VERSION ""

NS_ :

BS_:

BU_: ECU_Engine ECU_Transmission ECU_ABS ECU_Body Gateway Cluster Diagnostic

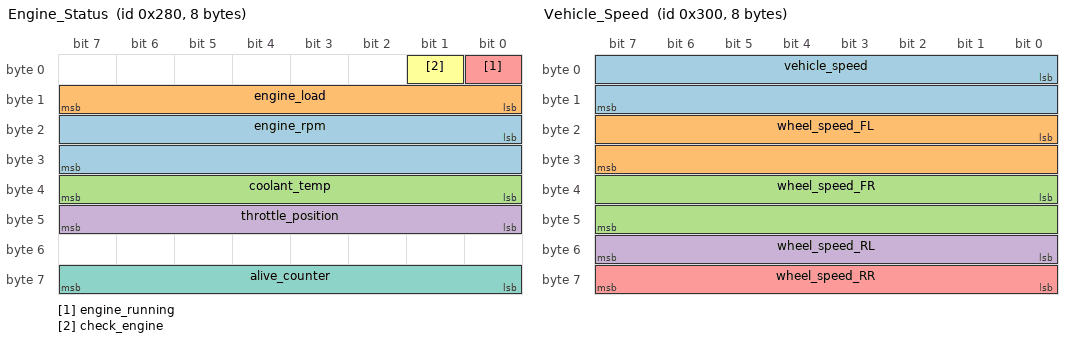
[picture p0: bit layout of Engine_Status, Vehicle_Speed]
BO_ 640 Engine_Status: 8 ECU_Engine
 SG_ engine_rpm : 16|16@1+ (0.25,0) [0|8000] "rpm" Cluster
 SG_ engine_load : 8|8@1+ (0.3921569,0) [0|100] "%" Cluster
 SG_ coolant_temp : 32|8@1+ (1,-40) [-40|215] "degC" Cluster
 SG_ throttle_position : 40|8@1+ (0.3921569,0) [0|100] "%" Cluster
 SG_ engine_running : 0|1@1+ (1,0) [0|1] "" Cluster
 SG_ check_engine : 1|1@1+ (1,0) [0|1] "" Cluster
 SG_ alive_counter : 56|8@1+ (1,0) [0|255] "" Cluster

BO_ 768 Vehicle_Speed: 8 ECU_ABS
 SG_ vehicle_speed : 0|16@1+ (0.01,0) [0|250] "km/h" Cluster
 SG_ wheel_speed_FL : 16|16@1+ (0.01,0) [0|250] "km/h" ECU_ABS
 SG_ wheel_speed_FR : 32|16@1+ (0.01,0) [0|250] "km/h" ECU_ABS
 SG_ wheel_speed_RL : 48|8@1+ (1,0) [0|250] "km/h" ECU_ABS
 SG_ wheel_speed_RR : 56|8@1+ (1,0) [0|250] "km/h" ECU_ABS

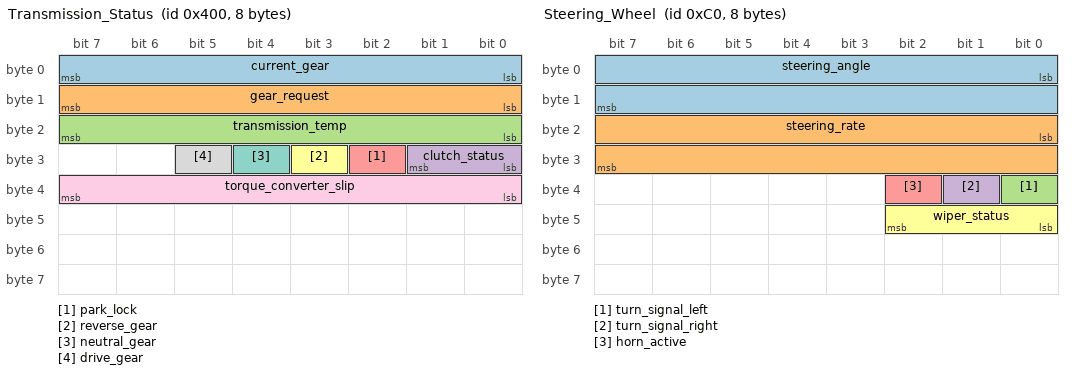
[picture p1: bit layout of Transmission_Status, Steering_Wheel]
BO_ 1024 Transmission_Status: 8 ECU_Transmission
 SG_ current_gear : 0|8@1+ (1,0) [0|8] "" Cluster
 SG_ gear_request : 8|8@1+ (1,0) [0|8] "" ECU_Transmission
 SG_ transmission_temp : 16|8@1+ (1,-40) [-40|150] "degC" Cluster
 SG_ clutch_status : 24|2@1+ (1,0) [0|3] "" ECU_Transmission
 SG_ park_lock : 26|1@1+ (1,0) [0|1] "" ECU_Transmission
 SG_ reverse_gear : 27|1@1+ (1,0) [0|1] "" Cluster
 SG_ neutral_gear : 28|1@1+ (1,0) [0|1] "" Cluster
 SG_ drive_gear : 29|1@1+ (1,0) [0|1] "" Cluster
 SG_ torque_converter_slip : 32|8@1+ (0.390625,0) [0|100] "%" ECU_Transmission

BO_ 192 Steering_Wheel: 8 ECU_Body
 SG_ steering_angle : 0|16@1- (0.043,0) [-780|780] "deg" ECU_ABS
 SG_ steering_rate : 16|16@1- (0.5,0) [-1000|1000] "deg/s" ECU_ABS
 SG_ turn_signal_left : 32|1@1+ (1,0) [0|1] "" Cluster
 SG_ turn_signal_right : 33|1@1+ (1,0) [0|1] "" Cluster
 SG_ horn_active : 34|1@1+ (1,0) [0|1] "" ECU_Body
 SG_ wiper_status : 40|3@1+ (1,0) [0|7] "" ECU_Body

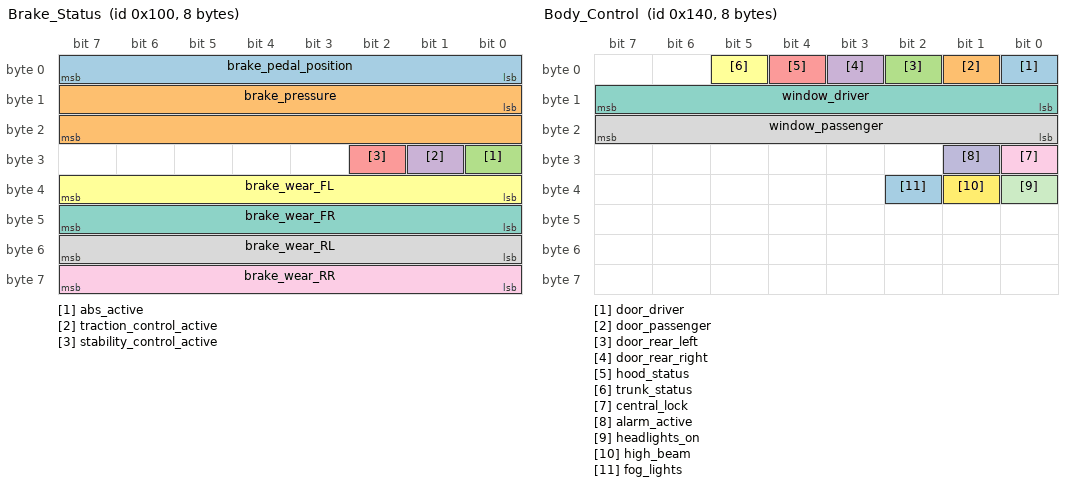
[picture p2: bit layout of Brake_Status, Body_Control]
BO_ 256 Brake_Status: 8 ECU_ABS
 SG_ brake_pedal_position : 0|8@1+ (0.3921569,0) [0|100] "%" ECU_Engine
 SG_ brake_pressure : 8|16@1+ (0.1,0) [0|300] "bar" ECU_ABS
 SG_ abs_active : 24|1@1+ (1,0) [0|1] "" Cluster
 SG_ traction_control_active : 25|1@1+ (1,0) [0|1] "" Cluster
 SG_ stability_control_active : 26|1@1+ (1,0) [0|1] "" Cluster
 SG_ brake_wear_FL : 32|8@1+ (0.3921569,0) [0|100] "%" Cluster
 SG_ brake_wear_FR : 40|8@1+ (0.3921569,0) [0|100] "%" Cluster
 SG_ brake_wear_RL : 48|8@1+ (0.3921569,0) [0|100] "%" Cluster
 SG_ brake_wear_RR : 56|8@1+ (0.3921569,0) [0|100] "%" Cluster

BO_ 320 Body_Control: 8 ECU_Body
 SG_ door_driver : 0|1@1+ (1,0) [0|1] "" Cluster
 SG_ door_passenger : 1|1@1+ (1,0) [0|1] "" Cluster
 SG_ door_rear_left : 2|1@1+ (1,0) [0|1] "" Cluster
 SG_ door_rear_right : 3|1@1+ (1,0) [0|1] "" Cluster
 SG_ hood_status : 4|1@1+ (1,0) [0|1] "" Cluster
 SG_ trunk_status : 5|1@1+ (1,0) [0|1] "" Cluster
 SG_ window_driver : 8|8@1+ (0.3921569,0) [0|100] "%" ECU_Body
 SG_ window_passenger : 16|8@1+ (0.3921569,0) [0|100] "%" ECU_Body
 SG_ central_lock : 24|1@1+ (1,0) [0|1] "" ECU_Body
 SG_ alarm_active : 25|1@1+ (1,0) [0|1] "" Cluster
 SG_ headlights_on : 32|1@1+ (1,0) [0|1] "" Cluster
 SG_ high_beam : 33|1@1+ (1,0) [0|1] "" Cluster
 SG_ fog_lights : 34|1@1+ (1,0) [0|1] "" ECU_Body

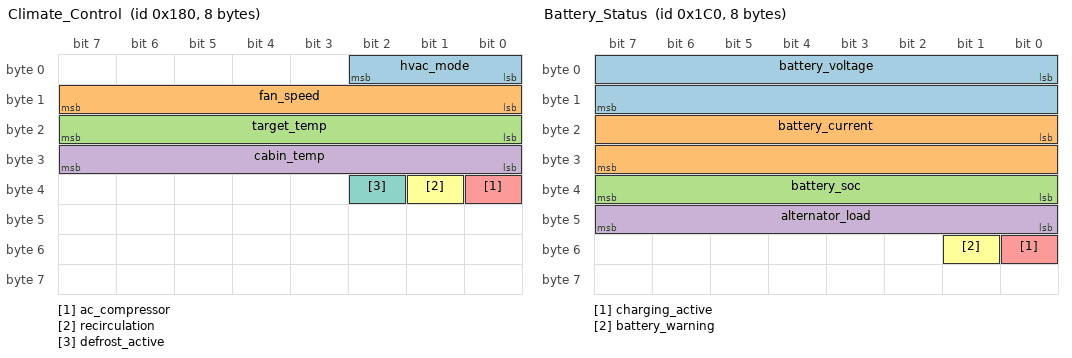
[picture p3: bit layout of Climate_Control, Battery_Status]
BO_ 384 Climate_Control: 8 ECU_Body
 SG_ hvac_mode : 0|3@1+ (1,0) [0|7] "" ECU_Body
 SG_ fan_speed : 8|8@1+ (1,0) [0|15] "" ECU_Body
 SG_ target_temp : 16|8@1+ (0.5,15) [15|30] "degC" ECU_Body
 SG_ cabin_temp : 24|8@1+ (0.5,-40) [-40|85] "degC" ECU_Body
 SG_ ac_compressor : 32|1@1+ (1,0) [0|1] "" ECU_Body
 SG_ recirculation : 33|1@1+ (1,0) [0|1] "" ECU_Body
 SG_ defrost_active : 34|1@1+ (1,0) [0|1] "" ECU_Body

BO_ 448 Battery_Status: 8 ECU_Engine
 SG_ battery_voltage : 0|16@1+ (0.01,0) [0|20] "V" Cluster
 SG_ battery_current : 16|16@1- (0.1,0) [-200|200] "A" ECU_Engine
 SG_ battery_soc : 32|8@1+ (0.5,0) [0|100] "%" Cluster
 SG_ alternator_load : 40|8@1+ (0.3921569,0) [0|100] "%" ECU_Engine
 SG_ charging_active : 48|1@1+ (1,0) [0|1] "" ECU_Engine
 SG_ battery_warning : 49|1@1+ (1,0) [0|1] "" Cluster

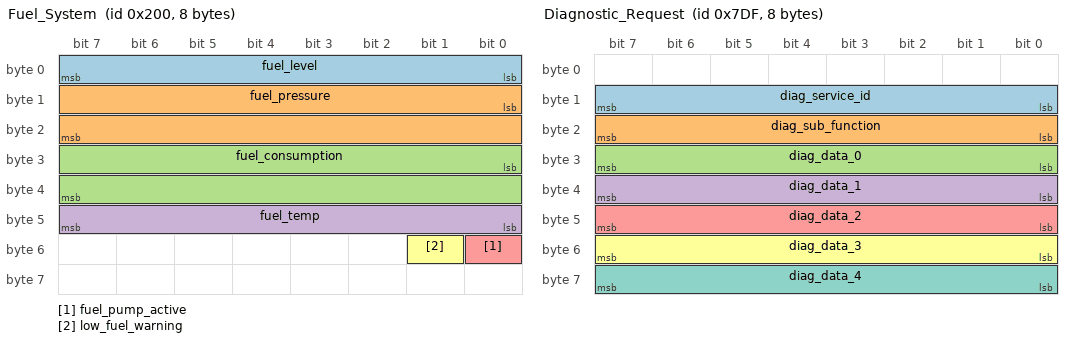
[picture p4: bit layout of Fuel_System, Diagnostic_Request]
BO_ 512 Fuel_System: 8 ECU_Engine
 SG_ fuel_level : 0|8@1+ (0.3921569,0) [0|100] "%" Cluster
 SG_ fuel_pressure : 8|16@1+ (0.1,0) [0|1000] "kPa" ECU_Engine
 SG_ fuel_consumption : 24|16@1+ (0.01,0) [0|100] "L/h" Cluster
 SG_ fuel_temp : 40|8@1+ (1,-40) [-40|120] "degC" ECU_Engine
 SG_ fuel_pump_active : 48|1@1+ (1,0) [0|1] "" ECU_Engine
 SG_ low_fuel_warning : 49|1@1+ (1,0) [0|1] "" Cluster

BO_ 2015 Diagnostic_Request: 8 Diagnostic
 SG_ diag_service_id : 8|8@1+ (1,0) [0|255] "" ECU_Engine,ECU_Transmission,ECU_ABS,ECU_Body
 SG_ diag_sub_function : 16|8@1+ (1,0) [0|255] "" ECU_Engine,ECU_Transmission,ECU_ABS,ECU_Body
 SG_ diag_data_0 : 24|8@1+ (1,0) [0|255] "" ECU_Engine,ECU_Transmission,ECU_ABS,ECU_Body
 SG_ diag_data_1 : 32|8@1+ (1,0) [0|255] "" ECU_Engine,ECU_Transmission,ECU_ABS,ECU_Body
 SG_ diag_data_2 : 40|8@1+ (1,0) [0|255] "" ECU_Engine,ECU_Transmission,ECU_ABS,ECU_Body
 SG_ diag_data_3 : 48|8@1+ (1,0) [0|255] "" ECU_Engine,ECU_Transmission,ECU_ABS,ECU_Body
 SG_ diag_data_4 : 56|8@1+ (1,0) [0|255] "" ECU_Engine,ECU_Transmission,ECU_ABS,ECU_Body

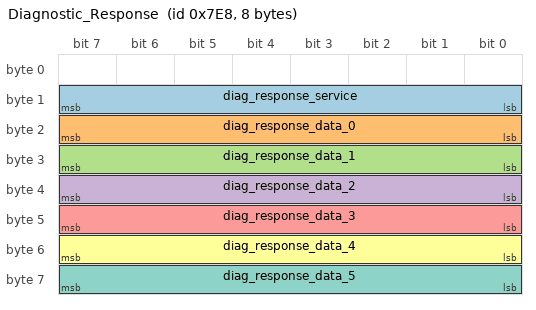
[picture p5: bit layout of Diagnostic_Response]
BO_ 2024 Diagnostic_Response: 8 ECU_Engine
 SG_ diag_response_service : 8|8@1+ (1,0) [0|255] "" Diagnostic
 SG_ diag_response_data_0 : 16|8@1+ (1,0) [0|255] "" Diagnostic
 SG_ diag_response_data_1 : 24|8@1+ (1,0) [0|255] "" Diagnostic
 SG_ diag_response_data_2 : 32|8@1+ (1,0) [0|255] "" Diagnostic
 SG_ diag_response_data_3 : 40|8@1+ (1,0) [0|255] "" Diagnostic
 SG_ diag_response_data_4 : 48|8@1+ (1,0) [0|255] "" Diagnostic
 SG_ diag_response_data_5 : 56|8@1+ (1,0) [0|255] "" Diagnostic

CM_ BU_ ECU_Engine "Engine Control Unit";
CM_ BU_ ECU_Transmission "Transmission Control Unit";
CM_ BU_ ECU_ABS "Anti-lock Braking System / Electronic Stability Control";
CM_ BU_ ECU_Body "Body Control Module";
CM_ BU_ Gateway "CAN Gateway";
CM_ BU_ Cluster "Instrument Cluster";
CM_ BU_ Diagnostic "Diagnostic Tester";

CM_ BO_ 640 "Engine status and vital parameters";
CM_ BO_ 768 "Vehicle and wheel speeds from ABS module";
CM_ BO_ 1024 "Transmission status and gear information";
CM_ BO_ 192 "Steering wheel position and controls";
CM_ BO_ 256 "Brake system status and pressure";
CM_ BO_ 320 "Body control (doors, windows, lights)";
CM_ BO_ 384 "HVAC and climate control";
CM_ BO_ 448 "Battery and charging system";
CM_ BO_ 512 "Fuel system monitoring";
CM_ BO_ 2015 "OBD-II / UDS diagnostic request (0x7DF)";
CM_ BO_ 2024 "OBD-II / UDS diagnostic response (0x7E8)";

CM_ SG_ 640 engine_rpm "Engine speed in revolutions per minute";
CM_ SG_ 640 engine_load "Calculated engine load percentage";
CM_ SG_ 640 coolant_temp "Engine coolant temperature";
CM_ SG_ 640 throttle_position "Throttle pedal position percentage";
CM_ SG_ 640 engine_running "Engine running status (0=off, 1=running)";
CM_ SG_ 640 check_engine "Check engine light / MIL status";
CM_ SG_ 640 alive_counter "Rolling counter for message aliveness";

CM_ SG_ 768 vehicle_speed "Vehicle speed calculated from wheel speeds";
CM_ SG_ 768 wheel_speed_FL "Front left wheel speed";
CM_ SG_ 768 wheel_speed_FR "Front right wheel speed";
CM_ SG_ 768 wheel_speed_RL "Rear left wheel speed";
CM_ SG_ 768 wheel_speed_RR "Rear right wheel speed";

CM_ SG_ 1024 current_gear "Current engaged gear (0=Neutral, 1-8=Drive gears)";
CM_ SG_ 1024 transmission_temp "Transmission oil temperature";
CM_ SG_ 1024 park_lock "Park lock engaged (0=unlocked, 1=locked)";

CM_ SG_ 192 steering_angle "Steering wheel angle (negative=left, positive=right)";
CM_ SG_ 192 steering_rate "Rate of steering wheel rotation";

CM_ SG_ 256 brake_pedal_position "Brake pedal position percentage";
CM_ SG_ 256 brake_pressure "Hydraulic brake pressure";
CM_ SG_ 256 abs_active "ABS intervention active";
CM_ SG_ 256 traction_control_active "Traction control active";
CM_ SG_ 256 stability_control_active "Electronic stability control active";

CM_ SG_ 320 door_driver "Driver door status (0=closed, 1=open)";
CM_ SG_ 320 central_lock "Central locking engaged";
CM_ SG_ 320 alarm_active "Security alarm triggered";

CM_ SG_ 448 battery_voltage "12V battery voltage";
CM_ SG_ 448 battery_current "Battery current (positive=charging, negative=discharging)";
CM_ SG_ 448 battery_soc "Battery state of charge";

CM_ SG_ 512 fuel_level "Fuel tank level percentage";
CM_ SG_ 512 fuel_consumption "Instantaneous fuel consumption rate";

BA_DEF_ "BusType" STRING ;
BA_DEF_ BO_ "GenMsgCycleTime" INT 0 10000;
BA_DEF_ BO_ "GenMsgSendType" STRING ;

BA_DEF_DEF_ "BusType" "CAN";
BA_DEF_DEF_ "GenMsgCycleTime" 0;
BA_DEF_DEF_ "GenMsgSendType" "cyclic";

BA_ "GenMsgCycleTime" BO_ 640 10;
BA_ "GenMsgCycleTime" BO_ 768 20;
BA_ "GenMsgCycleTime" BO_ 1024 50;
BA_ "GenMsgCycleTime" BO_ 192 10;
BA_ "GenMsgCycleTime" BO_ 256 10;
BA_ "GenMsgCycleTime" BO_ 320 100;
BA_ "GenMsgCycleTime" BO_ 384 200;
BA_ "GenMsgCycleTime" BO_ 448 1000;
BA_ "GenMsgCycleTime" BO_ 512 500;
BA_ "GenMsgSendType" BO_ 2015 "event";
BA_ "GenMsgSendType" BO_ 2024 "event";

VAL_ 640 engine_running 0 "Engine_Off" 1 "Engine_Running" ;
VAL_ 640 check_engine 0 "No_Fault" 1 "Malfunction_Indicator_Lamp" ;
VAL_ 1024 current_gear 0 "Neutral" 1 "First" 2 "Second" 3 "Third" 4 "Fourth" 5 "Fifth" 6 "Sixth" 7 "Seventh" 8 "Eighth" ;
VAL_ 1024 clutch_status 0 "Released" 1 "Partial" 2 "Engaged" 3 "Unknown" ;
VAL_ 1024 park_lock 0 "Unlocked" 1 "Locked" ;
VAL_ 1024 reverse_gear 0 "Not_Reverse" 1 "Reverse" ;
VAL_ 1024 neutral_gear 0 "Not_Neutral" 1 "Neutral" ;
VAL_ 1024 drive_gear 0 "Not_Drive" 1 "Drive" ;
VAL_ 192 turn_signal_left 0 "Off" 1 "Blinking" ;
VAL_ 192 turn_signal_right 0 "Off" 1 "Blinking" ;
VAL_ 192 horn_active 0 "Off" 1 "Active" ;
VAL_ 192 wiper_status 0 "Off" 1 "Intermittent_1" 2 "Intermittent_2" 3 "Intermittent_3" 4 "Low" 5 "Medium" 6 "High" 7 "Wash" ;
VAL_ 256 abs_active 0 "Inactive" 1 "Active" ;
VAL_ 256 traction_control_active 0 "Inactive" 1 "Active" ;
VAL_ 256 stability_control_active 0 "Inactive" 1 "Active" ;
VAL_ 320 door_driver 0 "Closed" 1 "Open" ;
VAL_ 320 door_passenger 0 "Closed" 1 "Open" ;
VAL_ 320 door_rear_left 0 "Closed" 1 "Open" ;
VAL_ 320 door_rear_right 0 "Closed" 1 "Open" ;
VAL_ 320 hood_status 0 "Closed" 1 "Open" ;
VAL_ 320 trunk_status 0 "Closed" 1 "Open" ;
VAL_ 320 central_lock 0 "Unlocked" 1 "Locked" ;
VAL_ 320 alarm_active 0 "Off" 1 "Triggered" ;
VAL_ 320 headlights_on 0 "Off" 1 "On" ;
VAL_ 320 high_beam 0 "Off" 1 "On" ;
VAL_ 320 fog_lights 0 "Off" 1 "On" ;
VAL_ 384 hvac_mode 0 "Off" 1 "Face" 2 "Feet" 3 "Face_Feet" 4 "Defrost" 5 "Defrost_Feet" 6 "Auto" 7 "Manual" ;
VAL_ 384 ac_compressor 0 "Off" 1 "On" ;
VAL_ 384 recirculation 0 "Fresh_Air" 1 "Recirculate" ;
VAL_ 384 defrost_active 0 "Off" 1 "Active" ;
VAL_ 448 charging_active 0 "Not_Charging" 1 "Charging" ;
VAL_ 448 battery_warning 0 "Normal" 1 "Low_Voltage" ;
VAL_ 512 fuel_pump_active 0 "Off" 1 "Running" ;
VAL_ 512 low_fuel_warning 0 "OK" 1 "Low_Fuel" ;
